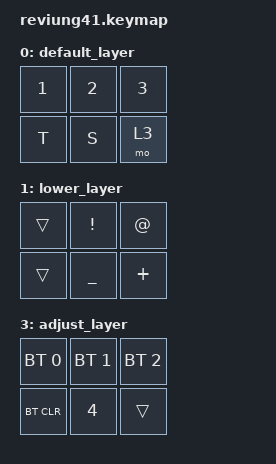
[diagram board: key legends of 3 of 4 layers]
/*
 * Copyright (c) 2020 The ZMK Contributors
 *
 * SPDX-License-Identifier: MIT
 */

#include <behaviors.dtsi>
#include <dt-bindings/zmk/keys.h>
#include <dt-bindings/zmk/bt.h>
#include <dt-bindings/zmk/rgb.h>

/ {
        keymap {
                compatible = "zmk,keymap";

                default_layer {
// -------------------------------------------------------------------------------------
// |  TAB |  Q  |  W  |  E  |  R  |  T  |   |  Y  |  U   |  I  |  O  |  P  |   BSPC    |
// | CTRL |  A  |  S  |  D  |  F  |  G  |   |  H  |  J   |  K  |  L  |  ;  |    '      |
// | SHFT |  Z  |  X  |  C  |  V  |  B  |   |  N  |  M   |  ,  |  .  |  /  | SHFT(RET) |
//                         | ALT | LWR | SPC | RSE  | ALT |
                        bindings = <
   &kp N1   &kp N2 &kp N3
   &kp T &kp S &mo 3
                        >;
                };

                lower_layer {
// ------------------------------------------------------------------------------------
// |    |  !  |  @  |  #  |  $  |  %  |   |  ^  |  &  |  *  |  (  |  )  |      DEL    |
// |    |  _  |  +  |  {  |  }  | "|" |   | LFT | DWN |  UP | RGT |  `  |       ~     |
// |    | ESC | GUI | ALT | CAPS|  "  |   | HOME| END | PGUP| PGDN| PRSC| SHFT(SPACE) |
//                       |     |     | RET | ADJ |     |
                        bindings = <
   &trans &kp EXCL  &kp AT  
   &trans &kp UNDER &kp PLUS
                        >;
                };

                raise_layer {
// ----------------------------------------------------------------------------
// |    |  1  |  2  |  3  |  4  |  5  |   |  6  |  7  |  8  |  9  |  0  | DEL |
// |    |  -  |  =  |  [  |  ]  |  \  |   | F1  | F2  | F3  | F4  | F5  | F6  |
// |    | ESC | GUI | ALT | CAPS|  "  |   | F7  | F8  | F9  | F10 | F11 | F12 |
//                       |     | ADJ | BSPC |    |     |
                        bindings = <
   &trans &kp MINUS &kp EQUAL &kp LBKT
   &trans &kp ESC   &kp LGUI  &kp RALT
                        >;
                };

                adjust_layer {
// -----------------------------------------------------------------------------------------
// | RGB BRI+ | RGB SAT+ | RGB HUE+ | RGB ANI+ |    | RGB TOG |   |  BT1  | BT2 | BT3 | BT4 | BT5 | BT CLR |
// | RGB BRI- | RGB SAT- | RGB HUE- | RGB ANI- |    |         |   |       |     |     |     |     |        |
// |          |          |          |          |    |         |   | RESET |     |     |     |     |        |
//                                              |     |     |     |     |     |
                        bindings = <
   &bt BT_SEL 0 &bt BT_SEL 1 &bt BT_SEL 2
   &bt BT_CLR    &kp N4      &trans 
                        >;
                };
        };
};
